# STM32L562 register map
File version: 1.1
Registers are 32-bit, read-write, reset 0x0 unless marked. A register's access mark holds for its fields unless they carry their own. Offsets are from the block's base; lines under a group give offsets from that group; [hi:lo] are bit positions; {n}, {i} and the like mark numbered series; 'fields as' and 'values as' point back to an identical list; <NAME> marks a mode.

## Memory map
0x50032C00 SEC_GTZC_MPCBB1 size 0x400

## SEC_GTZC_MPCBB1
Base 0x50032C00
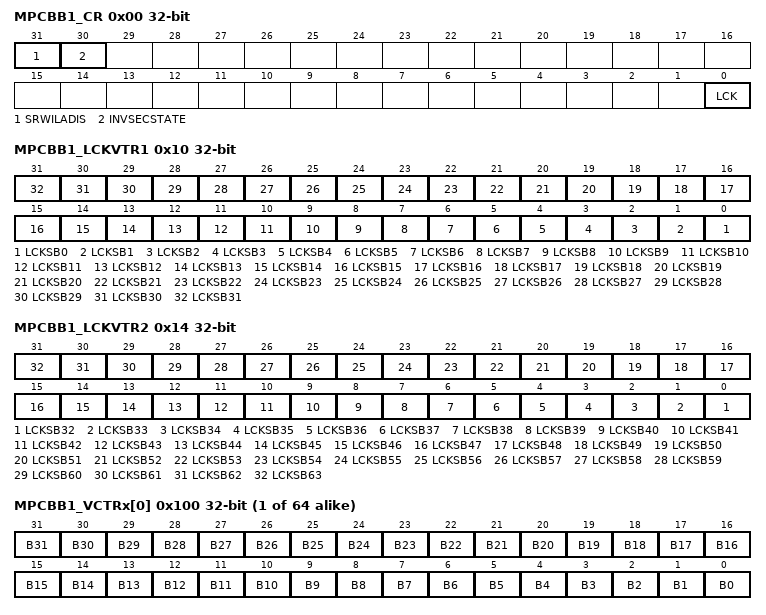
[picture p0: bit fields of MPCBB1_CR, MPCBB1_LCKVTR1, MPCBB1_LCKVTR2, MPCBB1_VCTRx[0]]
0x00 MPCBB1_CR — MPCBB control register
  [31] SRWILADIS, [30] INVSECSTATE, [0] LCK
0x10 MPCBB1_LCKVTR1 — MPCBB control register
  [n] LCKSB{n} (n=0..31)
0x14 MPCBB1_LCKVTR2 — MPCBB control register
  [n-32] LCKSB{n} (n=32..63)
{0x100+4i} MPCBB1_VCTRx[{i}] (i=0..63)
  [n] B{n} (n=0..31)
